# PIC32CZ2051CA80176 device description
Architecture: CORTEX-M7; Family: PIC32C; Series: PIC32CZCA80
Registers are 32-bit, read-write, reset 0x0 unless marked. A register's access mark holds for its fields unless they carry their own. Offsets are from the block's base; [hi:lo] are bit positions; {n}, {i} and the like mark numbered series; 'fields as' and 'values as' point back to an identical list.

## MPU — Memory Protection Unit
Instances: MPU 0xE000ED90
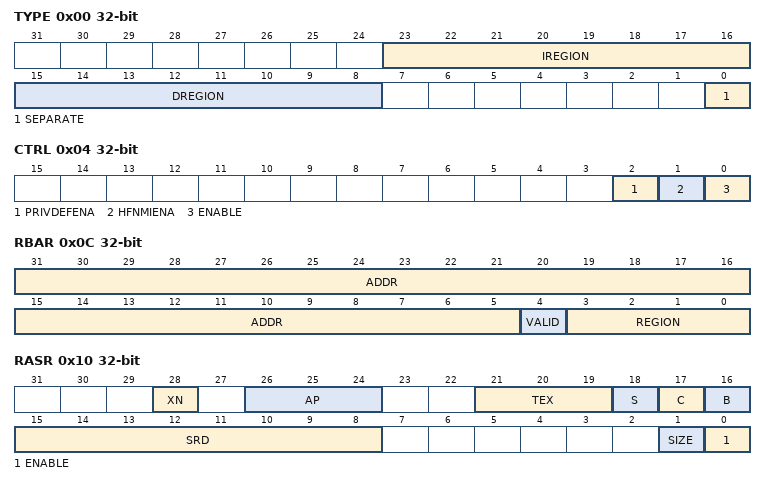
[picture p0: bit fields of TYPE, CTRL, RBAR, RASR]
0x00 TYPE ro reset not defined — MPU Type Register
  [23:16] IREGION — Number of Instruction Regions
  [15:8] DREGION — Number of Data Regions
  [0] SEPARATE — Separate instruction and Data Memory MapsRegions
0x04 CTRL — MPU Control Register
  [2] PRIVDEFENA — Enables privileged software access to default memory map
  [1] HFNMIENA — Enable Hard Fault and NMI handlers
  [0] ENABLE — MPU Enable
0x08 RNR reset not defined — MPU Region Number Register
  [7:0] REGION — Region referenced by RBAR and RASR
0x0C RBAR reset not defined — MPU Region Base Address Register
  [31:5] ADDR — Region base address
  [4] VALID — Region number valid
  [3:0] REGION — Region number
0x10 RASR reset not defined — MPU Region Attribute and Size Register
  [28] XN — Execute Never Attribute
  [26:24] AP — Access Permission
  [21:19] TEX — TEX bit
  [18] S — Shareable bit
  [17] C — Cacheable bit
  [16] B — Bufferable bit
  [15:8] SRD — Sub-region disable
  [1] SIZE — Region Size
  [0] ENABLE — Region Enable
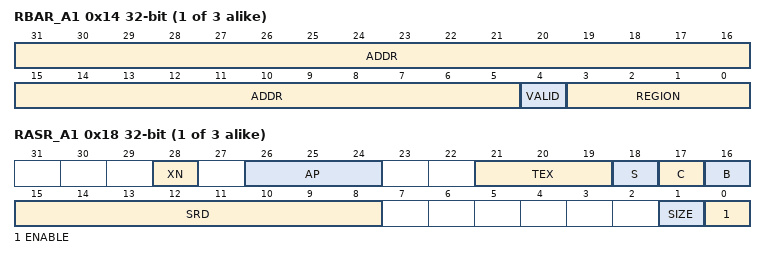
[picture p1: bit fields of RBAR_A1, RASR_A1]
{0xC+8i} RBAR_A{i} reset not defined (i=1..3) — MPU Alias {i} Region Base Address Register
  fields as RBAR
{0x10+8i} RASR_A{i} reset not defined (i=1..3) — MPU Alias {i} Region Attribute and Size Register
  fields as RASR

## NVIC — Nested Vectored Interrupt Controller
Instances: NVIC 0xE000E000
0x04 ICTR ro reset not defined — Interrupt Controller Type Register
  [3:0] INTLINESNUM — Number of 32-interrupt groups - 1
{0x100+4i} ISER[{i}] (i=0..6) — Interrupt Set Enable Register
  [31:0] SETENA — Interrupt set enable bits
{0x180+4i} ICER[{i}] (i=0..6) — Interrupt Clear Enable Register
  [31:0] CLRENA — Interrupt clear-enable bits
{0x200+4i} ISPR[{i}] (i=0..6) — Interrupt Set Pending Register
  [31:0] SETPEND — Interrupt set-pending bits
{0x280+4i} ICPR[{i}] (i=0..6) — Interrupt Clear Pending Register
  [31:0] CLRPEND — Interrupt clear-pending bits
{0x300+4i} IABR[{i}] (i=0..6) ro — Interrupt Active Bit Register
  [31:0] ACTIVE — Interrupt active bits
{0x400+i} IPR[{i}] (i=0..55) 8-bit — Interrupt Priority Register n
  [2:0] PRI0 — Priority of interrupt n

## OSC32KCTRL — 32kHz Oscillators Control
Instances: OSC32KCTRL 0x44042000
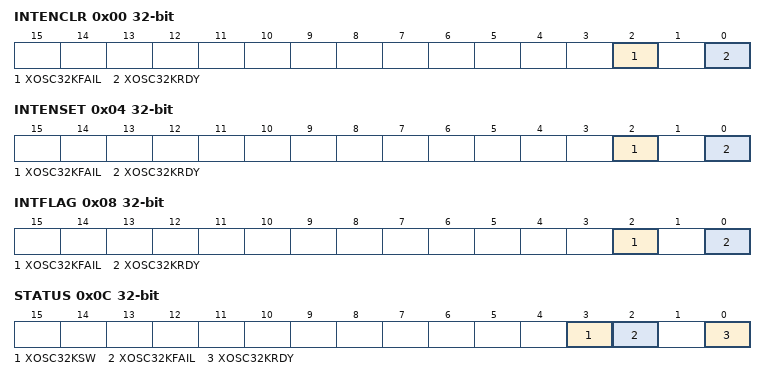
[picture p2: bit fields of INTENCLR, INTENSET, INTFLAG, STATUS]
0x00 INTENCLR (atomic clear) — Interrupt Enable Clear
  [2] XOSC32KFAIL — XOSC32K Clock Failure Detector Interrupt Enable
  [0] XOSC32KRDY — XOSC32K Ready Interrupt Enable
0x04 INTENSET (atomic set) — Interrupt Enable Set
  fields as INTENCLR
0x08 INTFLAG (atomic clear) — Interrupt Flag Status and Clear
  [2] XOSC32KFAIL — XOSC32K Clock Failure Detector
  [0] XOSC32KRDY — XOSC32K Ready
0x0C STATUS ro — Power and Clocks Status
  [3] XOSC32KSW — XOSC32K Clock switch
  [2] XOSC32KFAIL — XOSC32K Clock Failure Detector
  [0] XOSC32KRDY — XOSC32K Ready
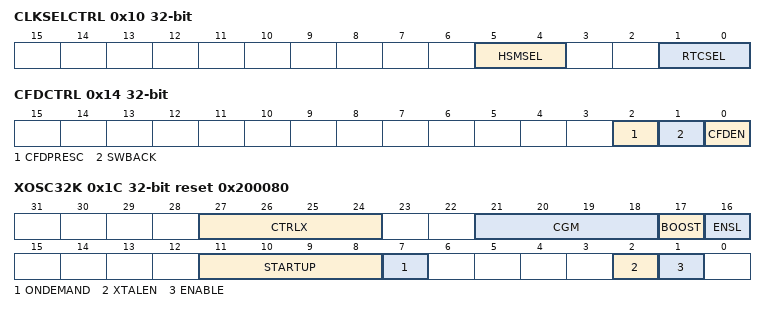
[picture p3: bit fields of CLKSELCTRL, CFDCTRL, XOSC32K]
0x10 CLKSELCTRL — Clock Selection Control
  [5:4] HSMSEL — HSM Clock Selection
    0=ULP32K (32.768kHz from 32kHz internal ULP oscillator); 2=XOSC32K (32.768kHz from 32.768kHz external crystal oscillator)
  [1:0] RTCSEL — RTC Clock Selection
    0=ULP32K (32.768kHz from 32kHz internal ULP oscillator); 1=ULP1K (1.024kHz from 32kHz internal ULP oscillator); 2=XOSC32K (32.768kHz from 32.768kHz external crystal oscillator); 3=XOSC1K (1.024kHz from 32.768kHz internal oscillator)
0x14 CFDCTRL — Clock Failure Detector Control
  [2] CFDPRESC — Clock Failure Detector Prescaler
  [1] SWBACK — Clock Switch Back
  [0] CFDEN — Clock Failure Detector Enable
0x18 EVCTRL — Event Control
  [0] CFDEO — Clock Failure Detector Event Output Enable
0x1C XOSC32K reset 0x200080 — 32kHz External Crystal Oscillator (XOSC32K) Control
  [27:24] CTRLX — Extended Control
  [21:18] CGM — Control Gain Mode
    0=The lower Control Gain Mode value; {v}=A higher Control Gain Mode value than CGM{v-1} (v=1..14); 15=The highest Control Gain Mode value
  [17] BOOST — Gain Boost
  [16] ENSL — Enable Servo Loop
  [11:8] STARTUP — Startup Mode
    0=1CYCLE (1 ULP clock cycle); 1=16CYCLES (16 ULP clock cycles); 2=32CYCLES (32 ULP clock cycles); 3=2048CYCLES (2048 ULP clock cycles); 4=4096CYCLES (4096 ULP clock cycles); 5=8192CYCLES (8192 ULP clock cycles); 6=16384CYCLES (16384 ULP clock cycles); 7=32768CYCLES (32768 ULP clock cycles); 8=65536CYCLES (65536 ULP clock cycles); 9=131072CYCLES (131072 ULP clock cycles); 10=262144CYCLES (262144 ULP clock cycles)
  [7] ONDEMAND — On Demand Mode
  [2] XTALEN — Crystal Oscillator Enable
  [1] ENABLE — Oscillator Enable

## Notices in the file
Copyright (c) 2021 Microchip Technology Inc.
SPDX-License-Identifier: Apache-2.0
Licensed under the Apache License, Version 2.0 (the "License");
you may not use this file except in compliance with the License.
You may obtain a copy of the License at
http://www.apache.org/licenses/LICENSE-2.0
Unless required by applicable law or agreed to in writing, software
distributed under the License is distributed on an "AS IS" BASIS,
WITHOUT WARRANTIES OR CONDITIONS OF ANY KIND, either express or implied.
See the License for the specific language governing permissions and
limitations under the License.
